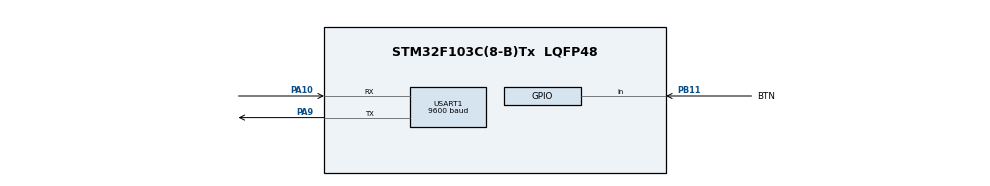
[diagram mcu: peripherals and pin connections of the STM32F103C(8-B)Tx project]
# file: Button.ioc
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Mcu.Family=STM32F1
Mcu.Name=STM32F103C(8-B)Tx
Mcu.Package=LQFP48
NVIC.PriorityGroup=NVIC_PRIORITYGROUP_4
PA10.Mode=Asynchronous
PA10.Signal=USART1_RX
PA13.Mode=Serial_Wire
PA13.Signal=SYS_JTMS-SWDIO
PA14.Mode=Serial_Wire
PA14.Signal=SYS_JTCK-SWCLK
PA9.Mode=Asynchronous
PA9.Signal=USART1_TX
PB11.GPIO_Label=BTN
PB11.GPIO_PuPd=GPIO_PULLUP
PB11.Signal=GPIO_Input
ProjectManager.HeapSize=0x200
ProjectManager.StackSize=0x400
ProjectManager.TargetToolchain=MDK-ARM V5.27
RCC.APB1Freq_Value=8000000
RCC.APB2Freq_Value=8000000
USART1.BaudRate=9600
USART1.VirtualMode=VM_ASYNC
board=custom

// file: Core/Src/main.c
/* USER CODE BEGIN Header */
/**
  ******************************************************************************
  * @file           : main.c
  * @brief          : Main program body
  ******************************************************************************
  * @attention
  *
  * Copyright (c) 2023 STMicroelectronics.
  * All rights reserved.
  *
  * This software is licensed under terms that can be found in the LICENSE file
  * in the root directory of this software component.
  * If no LICENSE file comes with this software, it is provided AS-IS.
  *
  ******************************************************************************
  */
/* USER CODE END Header */
#include "main.h"
#include "usart.h"
#include "gpio.h"

#include "Au_Button.h"

void SystemClock_Config(void);

/* USER CODE BEGIN 0 */
/*
  * @brief  串口重定向至printf
  * @param  ch:输出字符 , f:文件指针
  * @return ch:输出字符
  * @note   none
 */
int fputc(int ch, FILE *f)
{
    uint8_t temp[1] = {ch};
    HAL_UART_Transmit(&huart1, temp, 1, 2);
    return ch;
}

Button_T button1;

struct stu {
    int a;
    int b;
    int c;
    int d;
    int e;
};

void Button_Up_Cb(void* Btn)
{
    printf("释放\r\n");
}

void Button_Down_Cb(void* Btn)
{
    printf("Button 单击\r\n");
}

void Button_Double_Cb(void* Btn)
{
    printf("Button 双击\r\n");
}

void Button_Long_Free_Cb(void* Btn)
{
    printf("Button 长按\r\n");
}

uint8_t Read_Pin(void)
{
    return HAL_GPIO_ReadPin(BTN_GPIO_Port, BTN_Pin);
}

void Test_Init()
{
    Button_Create("TestButton", &button1, Read_Pin, GPIO_PIN_RESET);

    //Button_Attach(&button1, BUTTON_UP, Button_Up_Cb);
    Button_Attach(&button1, BUTTON_DOWN, Button_Down_Cb);
    Button_Attach(&button1, BUTTON_DOUBLE, Button_Double_Cb);
    Button_Attach(&button1, BUTTON_LONG_FREE, Button_Long_Free_Cb);
}

struct stu student = {1,2,3,4,5};

/* USER CODE END 0 */

int main(void)
{

  /* MCU Configuration--------------------------------------------------------*/

  /* Reset of all peripherals, Initializes the Flash interface and the Systick. */
  HAL_Init();

  /* Configure the system clock */
  SystemClock_Config();

  /* Initialize all configured peripherals */
  MX_GPIO_Init();
  MX_USART1_UART_Init();
  /* USER CODE BEGIN 2 */

  printf("hello\r\n");
  HAL_GPIO_WritePin(GPIOA, GPIO_PIN_0, GPIO_PIN_SET);

  /* USER CODE END 2 */

  /* Infinite loop */
  /* USER CODE BEGIN WHILE */
  Test_Init();
  while (1)
  {
      Button_Handle();
      HAL_Delay(20);
    /* USER CODE END WHILE */

  }
}

void SystemClock_Config(void)
{
  RCC_OscInitTypeDef RCC_OscInitStruct = {0};
  RCC_ClkInitTypeDef RCC_ClkInitStruct = {0};

  /** Initializes the RCC Oscillators according to the specified parameters
  * in the RCC_OscInitTypeDef structure.
  */
  RCC_OscInitStruct.OscillatorType = RCC_OSCILLATORTYPE_HSI;
  RCC_OscInitStruct.HSIState = RCC_HSI_ON;
  RCC_OscInitStruct.HSICalibrationValue = RCC_HSICALIBRATION_DEFAULT;
  RCC_OscInitStruct.PLL.PLLState = RCC_PLL_NONE;
  if (HAL_RCC_OscConfig(&RCC_OscInitStruct) != HAL_OK)
  {
    Error_Handler();
  }

  /** Initializes the CPU, AHB and APB buses clocks
  */
  RCC_ClkInitStruct.ClockType = RCC_CLOCKTYPE_HCLK|RCC_CLOCKTYPE_SYSCLK
                              |RCC_CLOCKTYPE_PCLK1|RCC_CLOCKTYPE_PCLK2;
  RCC_ClkInitStruct.SYSCLKSource = RCC_SYSCLKSOURCE_HSI;
  RCC_ClkInitStruct.AHBCLKDivider = RCC_SYSCLK_DIV1;
  RCC_ClkInitStruct.APB1CLKDivider = RCC_HCLK_DIV1;
  RCC_ClkInitStruct.APB2CLKDivider = RCC_HCLK_DIV1;

  if (HAL_RCC_ClockConfig(&RCC_ClkInitStruct, FLASH_LATENCY_0) != HAL_OK)
  {
    Error_Handler();
  }
}

void Error_Handler(void)
{
  __disable_irq();
  while (1)
  {
  }
}
